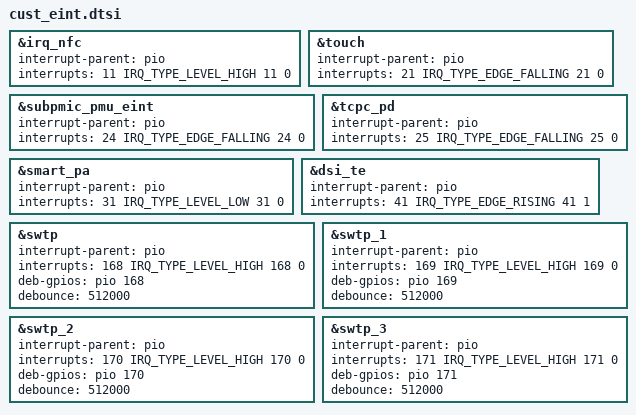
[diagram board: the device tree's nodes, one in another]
/*
 * Generated by MTK SP DrvGen Version: 3.5.160809 for MT6893.
 * 2023-06-02 17:19:58
 * Do Not Modify The File.
 * Copyright Mediatek Inc. (c) 2016.
*/

/*************************
 * EINT DTSI File
*************************/

#include <dt-bindings/interrupt-controller/irq.h>
#include <dt-bindings/interrupt-controller/arm-gic.h>

&irq_nfc {
	interrupt-parent = <&pio>;
	interrupts = <11 IRQ_TYPE_LEVEL_HIGH 11 0>;
	status = "okay";
};

&touch {
	interrupt-parent = <&pio>;
	interrupts = <21 IRQ_TYPE_EDGE_FALLING 21 0>;
	status = "okay";
};

&subpmic_pmu_eint {
	interrupt-parent = <&pio>;
	interrupts = <24 IRQ_TYPE_EDGE_FALLING 24 0>;
	status = "okay";
};

&tcpc_pd {
	interrupt-parent = <&pio>;
	interrupts = <25 IRQ_TYPE_EDGE_FALLING 25 0>;
	status = "okay";
};

&smart_pa {
	interrupt-parent = <&pio>;
	interrupts = <31 IRQ_TYPE_LEVEL_LOW 31 0>;
	status = "okay";
};

&dsi_te {
	interrupt-parent = <&pio>;
	interrupts = <41 IRQ_TYPE_EDGE_RISING 41 1>;
	status = "okay";
};

&swtp {
	interrupt-parent = <&pio>;
	interrupts = <168 IRQ_TYPE_LEVEL_HIGH 168 0>;
	deb-gpios = <&pio 168 0>;
	debounce = <512000>;
	status = "okay";
};

&swtp_1 {
	interrupt-parent = <&pio>;
	interrupts = <169 IRQ_TYPE_LEVEL_HIGH 169 0>;
	deb-gpios = <&pio 169 0>;
	debounce = <512000>;
	status = "okay";
};

&swtp_2 {
	interrupt-parent = <&pio>;
	interrupts = <170 IRQ_TYPE_LEVEL_HIGH 170 0>;
	deb-gpios = <&pio 170 0>;
	debounce = <512000>;
	status = "okay";
};

&swtp_3 {
	interrupt-parent = <&pio>;
	interrupts = <171 IRQ_TYPE_LEVEL_HIGH 171 0>;
	deb-gpios = <&pio 171 0>;
	debounce = <512000>;
	status = "okay";
};

